# M253 register map
File version: 1.0
Registers are 32-bit, read-write, reset 0x0 unless marked. A register's access mark holds for its fields unless they carry their own. Offsets are from the block's base; [hi:lo] are bit positions; {n}, {i} and the like mark numbered series; 'fields as' and 'values as' point back to an identical list.

## CLK — CLK Register Map
Base 0x40000200
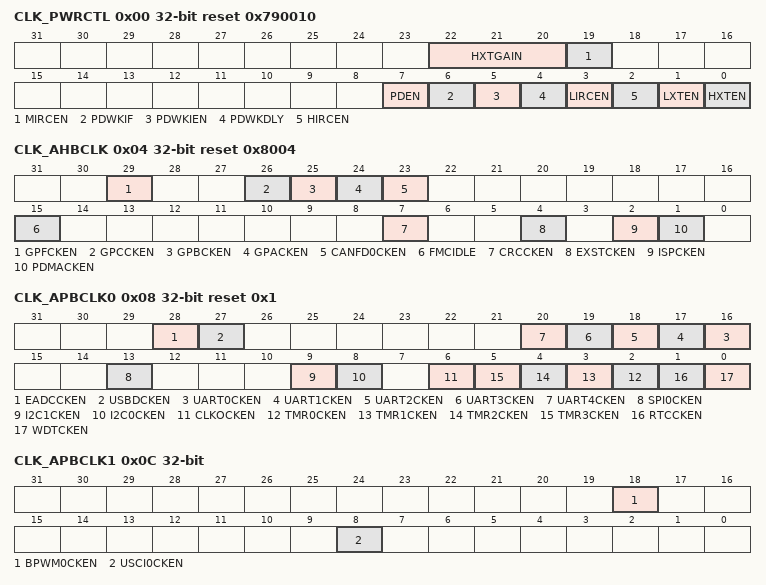
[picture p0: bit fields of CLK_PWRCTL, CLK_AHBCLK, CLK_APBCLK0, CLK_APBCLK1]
0x00 CLK_PWRCTL reset 0x790010 (reset mask 0xFFFF0FF0) — System Power-down Control Register
  [22:20] HXTGAIN — HXT Gain Control Bit (Write Protect). This is a protected register. Please refer to open lock sequence to program it. Gain control is used to enlarge the gain of crystal to make sure crystal work normally. If gain control is enabled, crystal will consume more power than gain control off. Note 1: This bit is write protected. Refer to the SYS_REGLCTL register. Note 2: Reset by power on reset.
    0=HXT frequency 1~4 MHz; 1=HXT frequency 4~8 MHz; 2=HXT frequency 8~12 MHz; 3=HXT frequency 12~ 16 MHz; 4=HXT frequency 16~24 MHz; 5=HXT frequency 24~32 MHz; 6=HXT frequency 24~32 MHz; 7=HXT frequency 24~32 MHz
  [19] MIRCEN — MIRC Enable Bit (Write Protect)
    0=4 MHz internal high speed RC oscillator (MIRC) Disabled; 1=4 MHz internal high speed RC oscillator (MIRC) Enabled
  [7] PDEN — System Power-down Enable (Write Protect). When this bit is set to 1, Power-down mode is enabled, chip enters Power-down mode immediately after the PDEN bit set. When chip wakes up from Power-down mode, this bit is auto cleared. Users need to set this bit again for next Power-down. In Power-down mode, HXT ,MIRC and HIRC will be disabled in this mode, but LXT and LIRC are not controlled by Power-down mode. In Power-down mode, the HCLK, PCLK0 and PCLK1 clocks are disabled, and ignored the clock source selection. The clocks of peripheral are not controlled by Power-down mode, if the peripheral clock source is from LXT or LIRC. Note: This bit is write protected. Refer to the SYS_REGLCTL register.
    0=Chip operating normally or chip in idle mode because of WFI command; 1=Chip enters Power-down mode instantly or wait CPU sleep command WFI
  [6] PDWKIF — Power-down Mode Wake-up Interrupt Status. Set by 'Power-down wake-up event' indicates that resume from Power-down mode' The flag is set if any wake-up source is occurred. Refer to Power Modes and Wake-up Sources section. Note 1: Write 1 to clear the bit to 0. Note 2: This bit works only if PDWKIEN (CLK_PWRCTL[5]) is set to 1.
  [5] PDWKIEN — Power-down Mode Wake-up Interrupt Enable Bit (Write Protect). Note 1: The interrupt will occur when both PDWKIF and PDWKIEN are high. Note 2: This bit is write protected. Refer to the SYS_REGLCTL register.
    0=Power-down mode wake-up interrupt Disabled; 1=Power-down mode wake-up interrupt Enabled
  [4] PDWKDLY — Enable the Wake-up Delay Counter (Write Protect). When the chip wakes up from Power-down mode, the clock control will delay certain clock cycles to wait system clock stable. The delayed clock cycle is 4096 clock cycles when chip works at 4~32 MHz external high speed crystal oscillator (HXT), The delayed clock cycle is 512 clock cycles when chip works at 48 MHz internal high speed RC oscillator (HIRC). The delayed clock cycle is 32 clock cycles when chip works at 4 MHz internal median speed RC oscillator (MIRC). Note: This bit is write protected. Refer to the SYS_REGLCTL register.
    0=Clock cycles delay Disabled; 1=Clock cycles delay Enabled
  [3] LIRCEN — LIRC Enable Bit (Write Protect). Note 1: This bit is write protected. Refer to the SYS_REGLCTL register. Note 2: LIRC will also be forced on when 1. Power down and ~(CONFIG0[3] CONFIG0[4] ~CONFIG0[31] CONFIG0[30]) 2. Not power down and ~(CONFIG0[3] CONFIG0[4] CONFIG0[31])
    0=38.4 kHz internal low speed RC oscillator (LIRC) Disabled; 1=38.4 kHz internal low speed RC oscillator (LIRC) Enabled
  [2] HIRCEN — HIRC Enable Bit (Write Protect). Note: This bit is write protected. Refer to the SYS_REGLCTL register.
    0=48 MHz internal high speed RC oscillator (HIRC) Disabled; 1=48 MHz internal high speed RC oscillator (HIRC) Enabled
  [1] LXTEN — LXT Enable Bit (Write Protect). Note 1: This bit is write protected. Refer to the SYS_REGLCTL register. Note 2: Reset by RTC powr on reset.
    0=32.768 kHz external low speed crystal (LXT) Disabled; 1=32.768 kHz external low speed crystal (LXT) Enabled
  [0] HXTEN — HXT Enable Bit (Write Protect). Note 1: This bit is write protected. Refer to the SYS_REGLCTL register. Note 2: Reset by powr on reset.
    0=4~32 MHz external high speed crystal (HXT) Disabled; 1=4~32 MHz external high speed crystal (HXT) Enabled
0x04 CLK_AHBCLK reset 0x8004 — AHB Devices Clock Enable Control Register
  [29] GPFCKEN — GPIOF Clock Enable Bit
    0=GPIOF port clock Disabled; 1=GPIOF port clock Enabled
  [26] GPCCKEN — GPIOC Clock Enable Bit
    0=GPIOC port clock Disabled; 1=GPIOC port clock Enabled
  [25] GPBCKEN — GPIOB Clock Enable Bit
    0=GPIOB port clock Disabled; 1=GPIOB port clock Enabled
  [24] GPACKEN — GPIOA Clock Enable Bit
    0=GPIOA port clock Disabled; 1=GPIOA port clock Enabled
  [23] CANFD0CKEN — CANFD0 Clock Enable Bit
    0=CANFD0 clock Disabled; 1=CANFD0 clock Enabled
  [15] FMCIDLE — Flash Memory Controller Clock Enable Bit in IDLE Mode
    0=FMC clock Disabled when chip is under IDLE mode; in this case, PDMA cannot access FMC memory; 1=FMC clock Enabled when chip is under IDLE mode; PDMA can access FMC memory
  [7] CRCCKEN — CRC Generator Controller Clock Enable Bit
    0=CRC peripheral clock Disabled; 1=CRC peripheral clock Enabled
  [4] EXSTCKEN — External System Tick Clock Enable Bit
    0=External System tick clock Disabled; 1=External System tick clock Enabled
  [2] ISPCKEN — Flash ISP Controller Clock Enable Bit
    0=Flash ISP peripheral clock Disabled; 1=Flash ISP peripheral clock Enabled
  [1] PDMACKEN — PDMA Controller Clock Enable Bit
    0=PDMA peripheral clock Disabled; 1=PDMA peripheral clock Enabled
0x08 CLK_APBCLK0 reset 0x1 — APB Devices Clock Enable Control Register 0
  [28] EADCCKEN — Enhanced Analog-digital-converter (EADC) Clock Enable Bit
    0=EADC clock Disabled; 1=EADC clock Enabled
  [27] USBDCKEN — USB Device Clock Enable Bit
    0=USB Device clock Disabled; 1=USB Device clock Enabled
  [n+16] UART{n}CKEN (n=0..4) — UART{n} Clock Enable Bit
    0=UART{n} clock Disabled; 1=UART{n} clock Enabled
  [13] SPI0CKEN — SPI0 Clock Enable Bit
    0=SPI0 clock Disabled; 1=SPI0 clock Enabled
  [9] I2C1CKEN — I2C1 Clock Enable Bit
    0=I2C1 clock Disabled; 1=I2C1 clock Enabled
  [8] I2C0CKEN — I2C0 Clock Enable Bit
    0=I2C0 clock Disabled; 1=I2C0 clock Enabled
  [6] CLKOCKEN — CLKO Clock Enable Bit
    0=CLKO clock Disabled; 1=CLKO clock Enabled
  [n+2] TMR{n}CKEN (n=0..3) — Timer{n} Clock Enable Bit
    0=Timer{n} clock Disabled; 1=Timer{n} clock Enabled
  [1] RTCCKEN — Real-time-clock APB Interface Clock Enable Bit. This bit is used to control the RTC APB clock.
    0=RTC clock Disabled; 1=RTC clock Enabled
  [0] WDTCKEN — Watchdog Timer Clock Enable Bit (Write Protect). Note 1: This bit is write protected. Refer to the SYS_REGLCTL register. Note 2: This bit is forced to 1 when CONFIG0[3] or CONFIG0[4] or CONFIG0[31] is 0. Note 3: Reset by power on reset or watchdog reset or software chip reset.
    0=Watchdog timer clock Disabled; 1=Watchdog timer clock Enabled
0x0C CLK_APBCLK1 — APB Devices Clock Enable Control Register 1
  [18] BPWM0CKEN — BPWM0 Clock Enable Bit
    0=BPWM0 clock Disabled; 1=BPWM0 clock Enabled
  [8] USCI0CKEN — USCI0 Clock Enable Bit
    0=USCI0 clock Disabled; 1=USCI0 clock Enabled
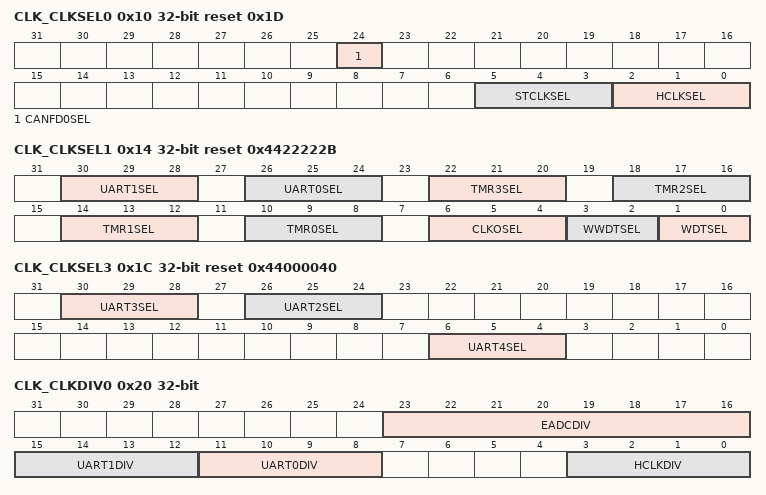
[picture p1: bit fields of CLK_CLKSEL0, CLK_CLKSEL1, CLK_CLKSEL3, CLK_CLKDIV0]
0x10 CLK_CLKSEL0 reset 0x1D — Clock Source Select Control Register 0
  [24] CANFD0SEL — CANFD0 Clock Source Selection
    0=Clock source from HCLK; 1=Clock source from HXT
  [5:3] STCLKSEL — Cortex-M23 SysTick Clock Source Selection (Write Protect). Note 2: This bit is write protected. Refer to the SYS_REGLCTL register.
    0=Clock source from HXT; 1=Clock source from LXT; 2=Clock source from HXT/2; 3=Clock source from HCLK/2; 7=Clock source from HIRC/2
  [2:0] HCLKSEL — HCLK Clock Source Selection (Write Protect). Before clock switching, the related clock sources (both pre-select and new-select) must be turned on. Note 1: This bit is write protected. Refer to the SYS_REGLCTL register. Note 2: Reset by power on reset.
    0=Clock source from HXT; 1=Clock source from LXT; 3=Clock source from LIRC; 5=Clock source from MIRC; 7=Clock source from HIRC
0x14 CLK_CLKSEL1 reset 0x4422222B — Clock Source Select Control Register 1
  [30:28] UART1SEL — UART1 Clock Source Selection
    0=Clock source from 4~32 MHz external high speed crystal oscillator (HXT); 2=Clock source from 32.768 kHz external low speed crystal oscillator (LXT); 3=Clock source from 48 MHz internal high speed RC oscillator (HIRC); 4=Clock source from PCLK1; 5=Clock source from 38.4 kHz internal low speed RC oscillator (LIRC)
  [26:24] UART0SEL — UART0 Clock Source Selection
    0=Clock source from 4~32 MHz external high speed crystal oscillator (HXT); 2=Clock source from 32.768 kHz external low speed crystal oscillator (LXT); 3=Clock source from 48 MHz internal high speed RC oscillator (HIRC); 4=Clock source from PCLK0; 5=Clock source from 38.4 kHz internal low speed RC oscillator (LIRC)
  [22:20] TMR3SEL — TIMER3 Clock Source Selection
    0=Clock source from 4~32 MHz external high speed crystal oscillator (HXT); 1=Clock source from 32.768 kHz external low speed crystal oscillator (LXT); 2=Clock source from PCLK1; 3=Clock source from external clock T3 pin; 5=Clock source from 38.4 kHz internal low speed RC oscillator (LIRC); 7=Clock source from 48 MHz internal high speed RC oscillator (HIRC)
  [18:16] TMR2SEL — TIMER2 Clock Source Selection
    0=Clock source from 4~32 MHz external high speed crystal oscillator (HXT); 1=Clock source from 32.768 kHz external low speed crystal oscillator (LXT); 2=Clock source from PCLK1; 3=Clock source from external clock T2 pin; 5=Clock source from 38.4 kHz internal low speed RC oscillator (LIRC); 7=Clock source from 48 MHz internal high speed RC oscillator (HIRC)
  [14:12] TMR1SEL — TIMER1 Clock Source Selection
    0=Clock source from 4~32 MHz external high speed crystal oscillator (HXT); 1=Clock source from 32.768 kHz external low speed crystal oscillator (LXT); 2=Clock source from PCLK0; 3=Clock source from external clock T1 pin; 5=Clock source from 38.4 kHz internal low speed RC oscillator (LIRC); 7=Clock source from 48 MHz internal high speed RC oscillator (HIRC)
  [10:8] TMR0SEL — TIMER0 Clock Source Selection
    0=Clock source from 4~32 MHz external high speed crystal oscillator (HXT); 1=Clock source from 32.768 kHz external low speed crystal oscillator (LXT); 2=Clock source from PCLK0; 3=Clock source from external clock T0 pin; 5=Clock source from 38.4 kHz internal low speed RC oscillator (LIRC); 7=Clock source from 48 MHz internal high speed RC oscillator (HIRC)
  [6:4] CLKOSEL — Clock Divider Clock Source Selection
    0=Clock source from 4~32 MHz external high speed crystal oscillator (HXT); 1=Clock source from 32.768 kHz external low speed crystal oscillator (LXT); 2=Clock source from HCLK; 3=Clock source from 48 MHz internal high speed RC oscillator (HIRC); 4=Clock source from 38.4 kHz internal low speed RC oscillator (LIRC); 5=Clock source from 4 MHz internal medium speed RC oscillator (MIRC); 7=Clock source from USB SOF
  [3:2] WWDTSEL — Window Watchdog Timer Clock Source Selection (Write Protect)
    2=Clock source from HCLK/2048; 3=Clock source from 38.4 kHz internal low speed RC oscillator (LIRC)
  [1:0] WDTSEL — Watchdog Timer Clock Source Selection (Write Protect). Note 1: This bit is write protected. Refer to the SYS_REGLCTL register. Note 2: This bit is forced to 11 when CONFIG0[31] or CONFIG0[4] or CONFIG0[3] is 0.
    1=Clock source from 32.768 kHz external low speed crystal oscillator (LXT); 2=Clock source from HCLK/2048; 3=Clock source from 38.4 kHz internal low speed RC oscillator (LIRC)
0x18 CLK_CLKSEL2 reset 0x20 — Clock Source Select Control Register 2
  [5:4] SPI0SEL — SPI0 Clock Source Selection
    0=Clock source from 4~32 MHz external high speed crystal oscillator (HXT); 2=Clock source from PCLK1; 3=Clock source from 48 MHz internal high speed RC oscillator (HIRC)
0x1C CLK_CLKSEL3 reset 0x44000040 — Clock Source Select Control Register 3
  [30:28] UART3SEL — UART3 Clock Source Selection
    values as CLK_CLKSEL1.UART1SEL
  [26:24] UART2SEL — UART2 Clock Source Selection
    values as CLK_CLKSEL1.UART0SEL
  [6:4] UART4SEL — UART4 Clock Source Selection
    values as CLK_CLKSEL1.UART0SEL
0x20 CLK_CLKDIV0 — Clock Divider Number Register 0
  [23:16] EADCDIV — EADC Clock Divide Number From EADC Clock Source
  [15:12] UART1DIV — UART1 Clock Divide Number From UART1 Clock Source
  [11:8] UART0DIV — UART0 Clock Divide Number From UART0 Clock Source
  [3:0] HCLKDIV — HCLK Clock Divide Number From HCLK Clock Source. Note: This field is only reset by power on reset.
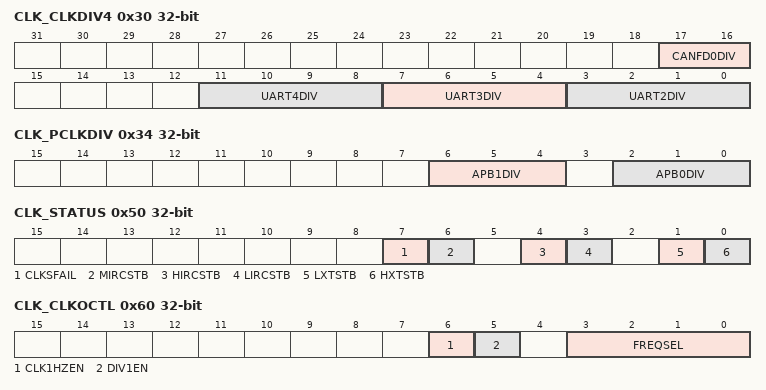
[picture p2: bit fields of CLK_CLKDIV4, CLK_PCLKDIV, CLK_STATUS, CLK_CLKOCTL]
0x30 CLK_CLKDIV4 — Clock Divider Number Register 4
  [17:16] CANFD0DIV — CANFD0 Clock Divide Number From CANFD0 Clock Source
  [11:8] UART4DIV — UART4 Clock Divide Number From UART4 Clock Source
  [7:4] UART3DIV — UART3 Clock Divide Number From UART3 Clock Source
  [3:0] UART2DIV — UART2 Clock Divide Number From UART2 Clock Source
0x34 CLK_PCLKDIV — APB Clock Divider Register
  [6:4] APB1DIV — APB1 Clock DIvider. APB1 clock can be divided from HCLK. Others: Reserved.
  [2:0] APB0DIV — APB0 Clock DIvider. APB0 clock can be divided from HCLK. Others: Reserved.
0x50 CLK_STATUS ro (reset mask 0xFFFFFF00) — Clock Status Monitor Register
  [7] CLKSFAIL — Clock Switching Fail Flag. This bit is updated when software switches system clock source. If switch target clock is stable, this bit will be set to 0. If switch target clock is not stable, this bit will be set to 1. Note: Write 1 to clear the bit to 0.
    0=Clock switching success; 1=Clock switching failure
  [6] MIRCSTB — MIRC Clock Source Stable Flag (Read Only)
    0=4 MHz internal mid speed RC oscillator (MIRC) clock is not stable or disabled; 1=4 MHz internal mid speed RC oscillator (MIRC) clock is stable and enabled
  [4] HIRCSTB — HIRC Clock Source Stable Flag (Read Only)
    0=48 MHz internal high speed RC oscillator (HIRC) clock is not stable or disabled; 1=48 MHz internal high speed RC oscillator (HIRC) clock is stable and enabled
  [3] LIRCSTB — LIRC Clock Source Stable Flag (Read Only)
    0=38.4 kHz internal low speed RC oscillator (LIRC) clock is not stable or disabled; 1=38.4 kHz internal low speed RC oscillator (LIRC) clock is stable and enabled
  [1] LXTSTB — LXT Clock Source Stable Flag (Read Only)
    0=32.768 kHz external low speed crystal oscillator (LXT) clock is not stable or disabled; 1=32.768 kHz external low speed crystal oscillator (LXT) clock is stabled and enabled
  [0] HXTSTB — HXT Clock Source Stable Flag (Read Only)
    0=4~32 MHz external high speed crystal oscillator (HXT) clock is not stable or disabled; 1=4~32 MHz external high speed crystal oscillator (HXT) clock is stable and enabled
0x60 CLK_CLKOCTL — Clock Output Control Register
  [6] CLK1HZEN — Clock Output 1Hz Enable Bit
    0=1 Hz clock output for 32.768 kHz frequency compensation Disabled; 1=1 Hz clock output for 32.768 kHz frequency compensation Enabled
  [5] DIV1EN — Clock Output Divide One Enable Bit
    0=Clock Output will output clock with source frequency divided by FREQSEL; 1=Clock Output will output clock with source frequency
  [3:0] FREQSEL — Clock Output Frequency Selection. The formula of output frequency is. Fin is the input clock frequency. Fout is the frequency of divider output clock. N is the 4-bit value of FREQSEL[3:0].
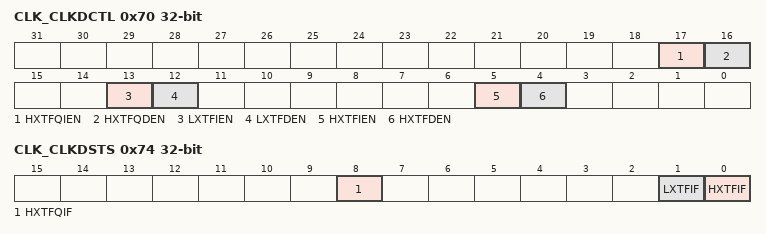
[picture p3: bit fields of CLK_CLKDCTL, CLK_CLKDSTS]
0x70 CLK_CLKDCTL — Clock Fail Detector Control Register
  [17] HXTFQIEN — HXT Clock Frequency Range Detector Interrupt Enable Bit
    0=4~32 MHz external high speed crystal oscillator (HXT) clock frequency range detector fail interrupt Disabled; 1=4~32 MHz external high speed crystal oscillator (HXT) clock frequency range detector fail interrupt Enabled
  [16] HXTFQDEN — HXT Clock Frequency Range Detector Enable Bit
    0=4~32 MHz external high speed crystal oscillator (HXT) clock frequency range detector Disabled; 1=4~32 MHz external high speed crystal oscillator (HXT) clock frequency range detector Enabled
  [13] LXTFIEN — LXT Clock Fail Interrupt Enable Bit
    0=32.768 kHz external low speed crystal oscillator (LXT) clock fail interrupt Disabled; 1=32.768 kHz external low speed crystal oscillator (LXT) clock fail interrupt Enabled
  [12] LXTFDEN — LXT Clock Fail Detector Enable Bit
    0=32.768 kHz external low speed crystal oscillator (LXT) clock fail detector Disabled; 1=32.768 kHz external low speed crystal oscillator (LXT) clock fail detector Enabled
  [5] HXTFIEN — HXT Clock Fail Interrupt Enable Bit
    0=4~32 MHz external high speed crystal oscillator (HXT) clock fail interrupt Disabled; 1=4~32 MHz external high speed crystal oscillator (HXT) clock fail interrupt Enabled
  [4] HXTFDEN — HXT Clock Fail Detector Enable Bit
    0=4~32 MHz external high speed crystal oscillator (HXT) clock fail detector Disabled; 1=4~32 MHz external high speed crystal oscillator (HXT) clock fail detector Enabled
0x74 CLK_CLKDSTS — Clock Fail Detector Status Register
  [8] HXTFQIF — HXT Clock Frequency Range Detector Interrupt Flag (Write Protect). Note: Write 1 to clear the bit to 0.
    0=4~32 MHz external high speed crystal oscillator (HXT) clock frequency is normal; 1=4~32 MHz external high speed crystal oscillator (HXT) clock frequency is abnormal
  [1] LXTFIF — LXT Clock Fail Interrupt Flag (Write Protect). Note: Write 1 to clear the bit to 0.
    0=32.768 kHz external low speed crystal oscillator (LXT) clock is normal; 1=32.768 kHz external low speed crystal oscillator (LXT) stops
  [0] HXTFIF — HXT Clock Fail Interrupt Flag (Write Protect). Note: Write 1 to clear the bit to 0.
    0=4~32 MHz external high speed crystal oscillator (HXT) clock is normal; 1=4~32 MHz external high speed crystal oscillator (HXT) clock stops
0x78 CLK_CDUPB — Clock Frequency Range Detector Upper Boundary Register
  [9:0] UPERBD — HXT Clock Frequency Range Detector Upper Boundary Value. The bits define the maximum value of frequency range detector window. When HXT frequency higher than this maximum frequency value, the HXT Clock Frequency Range Detector Interrupt Flag will set to 1. Note :Frequency out of range will be asserted when HIRC_period*512 HXT_period*CLK_DUPB or HIRC_period*512 HXT_period*CLK_CDLOWB.
0x7C CLK_CDLOWB — Clock Frequency Range Detector Lower Boundary Register
  [9:0] LOWERBD — HXT Clock Frequency Range Detector Lower Boundary Value. The bits define the minimum value of frequency range detector window. When HXT frequency lower than this minimum frequency value, the HXT Clock Frequency Range Detector Interrupt Flag will set to 1. Note :The frequency out of range will be asserted when HIRC_period*512 HXT_period*CLK_DUPB or HIRC_period*512 HXT_period*CLK_CDLOWB.
0x90 CLK_PMUCTL — Power Manager Control Register
  [2:0] PDMSEL — Power-down Mode Selection (Write Protect). This is a protected register. Please refer to open lock sequence to program it. These bits control chip power-down mode grade selection when CPU execute WFI/WFE instruction. Note: This bit is write protected. Refer to the SYS_REGLCTL register.
    0=Power-down mode is selected. (PD); 2=fast wake up; 6=Deep Power-down mode is selected (DPD)
0xB4 CLK_HXTFSEL (reset mask 0xFFFFFFF0) — HXT Filter Select Control Register
  [0] HXTFSEL — HXT Filter Select. Note 1: This bit is write protected. Refer to the SYS_REGLCTL register. Note 2: This bit should not be changed during HXT running.
    0=HXT frequency is greater than 12 MHz; 1=HXT frequency is less than or equal to 12 MHz
